# PCIe_SS1_PL_CONF register map
Vendor: Texas Instruments
Peripheral module from a debugger description file (folder DRA74xP_75xP_76xP_77xP).
Registers are 32-bit, read-write, reset 0x0 unless marked. A register's access mark holds for its fields unless they carry their own. Offsets are as the file gives them; lines under a group give offsets from that group; [hi:lo] are bit positions; {n}, {i} and the like mark numbered series; 'fields as' and 'values as' point back to an identical list; <NAME> marks a mode.

## PCIe_SS1_PL_CONF
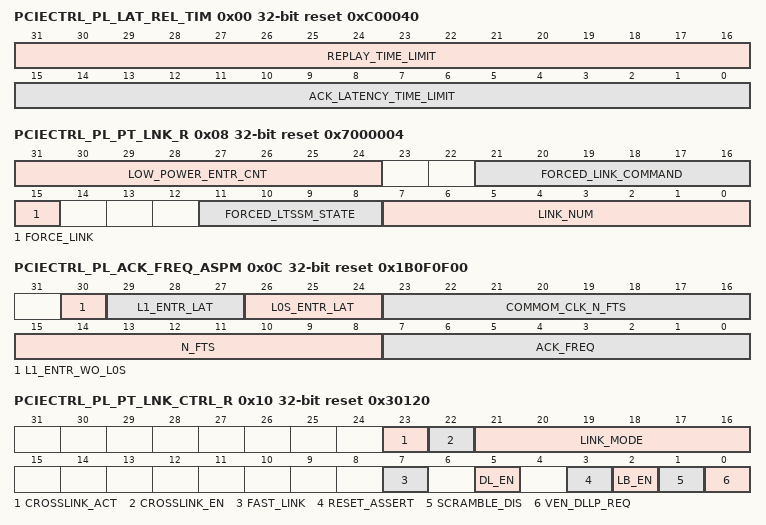
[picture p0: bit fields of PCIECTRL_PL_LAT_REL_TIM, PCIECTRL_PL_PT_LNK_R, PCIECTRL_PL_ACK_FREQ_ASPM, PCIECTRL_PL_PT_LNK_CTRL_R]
0x00 PCIECTRL_PL_LAT_REL_TIM reset 0xC00040 — Ack Latency and Replay Timer Register
  [31:16] REPLAY_TIME_LIMIT — The replay timer expires when it reaches this limit; The core initiates a replay upon reception of a Nak or when the replay timer expires; The default value depends on number of bytes (NB) per cycle, which is defined by the maximum core base frequency of the device PCIe core, corresponding to 250 MHz for PCIe-Gen2 (5 Gbps) operation. The default is then updated based on the Negotiated Link Width and Max_Payload_Size; Note: If operating at 5 Gb/s, then the rounded-up value of an additional (153/CX_NB) cycles is added, where CX_NB correspond to the number of PCIEPCS 8-bit input symbols per single 16-bit lane, that is, CX_NB=2. This means at 5Gbps, 77 extra cycles should be considered for the replay time limit. This is for additional internal processing for received TLPs and transmitted DLLPs.
  [15:0] ACK_LATENCY_TIME_LIMIT — The Ack/Nak latency timer expires when it reaches this limit; The default value depends on number of bytes (NB) per cycle, which is defined by the maximum core base frequency of the device PCIe core, corresponding to 250 MHz for PCIe-Gen2 (5 Gbps) operation. The default is then updated based on the Negotiated Link Width and Max_Payload_Size. Note: If operating at 5 Gb/s, then the rounded-up value of an additional (51 /CX_NB) cycles is added, where CX_NB correspond to the number of PCIEPCS 8-bit input symbols per single 16-bit lane, that is, CX_NB=2. This means at 5Gbps, 26 extra cycles should be considered for the acknowledge latency time limit. This is for additional internal processing for received TLPs and transmitted DLLPs.
0x04 PCIECTRL_PL_VENDOR_SPECIFIC_DLLP reset 0xFFFFFFFF — Vendor Specific DLLP Register
  [31:0] VEN_DLLP_REG — To send custom DLLP, write 8-bit DLLP Type and 24-bits of Payload data, then set PT_LNK_CTRL_R[0]
0x08 PCIECTRL_PL_PT_LNK_R access per field reset 0x7000004 — Port Force Link Register
  [31:24] LOW_POWER_ENTR_CNT rw — The Power Management state will wait for this many clock cycles for the associated completion of a CfgWr to D-state register to go low-power; This register is intended for applications that do not let the core handle a completion for configuration request to the PMCSCR register; Note: Only used in the DM core (in EP mode), EP core, and the Upstream Port of a Switch
  [21:16] FORCED_LINK_COMMAND rw — Link command transmitted by setting Force_Link (bit 15);
  [15] FORCE_LINK rw — Forces the LTSSM state and the Link command specified in this register; Self-clearing
    1=FORCE
  [11:8] FORCED_LTSSM_STATE rw — LTSSM state forced by setting Force_Link (bit 15)
  [7:0] LINK_NUM rw — Link Number; Not used for Endpoint
0x0C PCIECTRL_PL_ACK_FREQ_ASPM access per field reset 0x1B0F0F00 — Ack Frequency and L0-L1 ASPM Control Register (Sticky)
  [30] L1_ENTR_WO_L0S rw — Enter ASPM L1 without receive in L0s; Allow core to enter ASPM L1 even when link partner did not go to L0s (receive is not in L0s); When not set, core goes to ASPM L1 only after idle period during which both receive and transmit are in L0s
  [29:27] L1_ENTR_LAT rw — L1 Entrance Latency 0x0: 1 uS 0x1: 2 uS 0x2: 4 uS 0x3: 8 uS 0x4: 16 uS 0x5: 32 uS 0x6: 64 uS 0x7: 64 uS (alternate encoding)
  [26:24] L0S_ENTR_LAT rw — L0s Entrance Latency; Values correspond to: 0b000: 1 us 0b001: 2 us 0b010: 3 us 0b011: 4 us 0b100: 5 us 0b101: 6 us 0b110: 7 us 0b111: 7 us (alternate encoding)
  [23:16] COMMOM_CLK_N_FTS rw — Alternative N_FTS value, for common clock mode
  [15:8] N_FTS rw — Number of Fast Training Sequence (FTS) ordered sets to be transmitted when exiting L0s to L0; The maximum that can be requested is 255; Value 0 is not supported, and may cause LTSSM to go into Recovery upon L0s exit
  [7:0] ACK_FREQ rw — Ack Frequency; Number of pending ACKs accumulated before sending an ACK DLLP
0x10 PCIECTRL_PL_PT_LNK_CTRL_R access per field reset 0x30120 — Port Link Control Register (Sticky)
  [23] CROSSLINK_ACT ro — Crosslink Active
  [22] CROSSLINK_EN rw — Crosslink Enable
  [21:16] LINK_MODE rw — Link Mode Enable; Write 1 to bit N to enable (2**N)-lane mode 0x01: _1x 0x03: _2x 0x07: _4x
  [7] FAST_LINK rw — Fast Link Mode
  [5] DL_EN rw — DLL Link Enable
  [3] RESET_ASSERT rw
  [2] LB_EN rw — Loopback Enable
  [1] SCRAMBLE_DIS rw — Scramble Disable
  [0] VEN_DLLP_REQ rw — Vendor Specific DLLP transmit Request
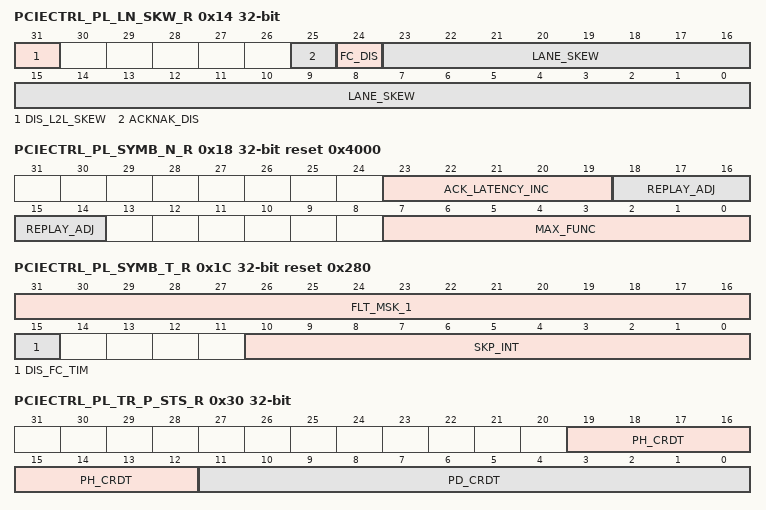
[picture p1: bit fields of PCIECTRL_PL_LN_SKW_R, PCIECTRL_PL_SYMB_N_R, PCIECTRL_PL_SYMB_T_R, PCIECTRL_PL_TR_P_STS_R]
0x14 PCIECTRL_PL_LN_SKW_R access per field — Lane Skew Register (Sticky)
  [31] DIS_L2L_SKEW rw — Disable Lane-to-Lane Deskew
  [25] ACKNAK_DIS rw — Ack/Nak Disable
  [24] FC_DIS rw — Flow Control Disable
  [23:0] LANE_SKEW rw — Insert Lane Skew for Transmit
0x18 PCIECTRL_PL_SYMB_N_R access per field reset 0x4000 — Timer Control and Symbol Number Register (Sticky)
  [23:19] ACK_LATENCY_INC rw — Timer Modifier for Ack/Nak Latency Timer
  [18:14] REPLAY_ADJ rw — Timer Modifier for Replay Timer
  [7:0] MAX_FUNC rw — Configuration Requests targeted at function numbers above this value will be returned with UR (unsupported request).
0x1C PCIECTRL_PL_SYMB_T_R access per field reset 0x280 — Symbol Timer Register and Filter Mask Register 1 (Sticky)
  [31:16] FLT_MSK_1 rw — Mask RADM Filtering and Error Handling Rules: Mask 1
  [15] DIS_FC_TIM rw — Disable FC Watchdog Timer
  [10:0] SKP_INT rw — SKP Interval Value minus one, PIPE clock cycles. (1 PIPE cycle = 2 symbols in 16-bit-per-lane PIPE)
0x20 PCIECTRL_PL_FL_MSK_R2 — Filter Mask Register 2 (Sticky)
  [31:0] FLT_MSK_2 — Mask RADM Filtering and Error Handling Rules: Mask 2
0x24 PCIECTRL_PL_OBNP_SUBREQ_CTRL access per field reset 0x1 — AXI Multiple Outbound Decomposed NP SubRequests Control Register (Sticky)
  [0] EN_OBNP_SUBREQ rw — Enable AXI Multiple Outbound Decomposed NP Sub-Requests.
0x30 PCIECTRL_PL_TR_P_STS_R ro — Transmit Posted FC Credit Status Register (Sticky)
  [19:12] PH_CRDT — Transmit Posted Header FC Credits
  [11:0] PD_CRDT — Transmit Posted Data FC Credits
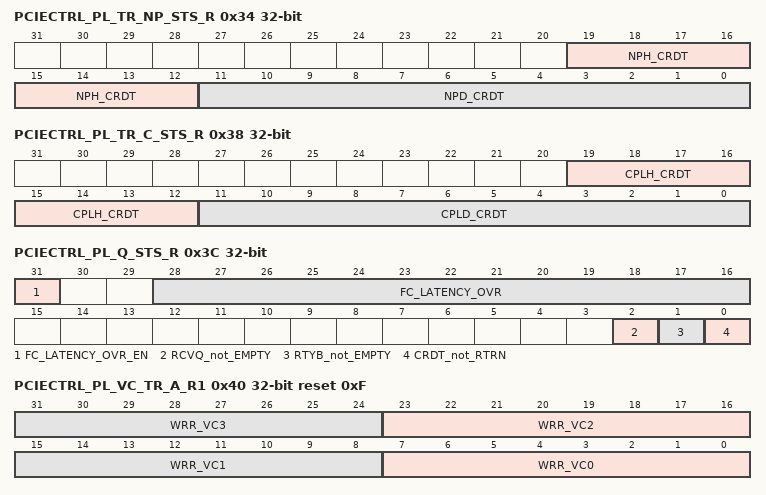
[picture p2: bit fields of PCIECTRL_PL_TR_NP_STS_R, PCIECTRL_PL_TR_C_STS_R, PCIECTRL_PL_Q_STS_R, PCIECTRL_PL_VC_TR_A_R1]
0x34 PCIECTRL_PL_TR_NP_STS_R ro — Transmit Non-Posted FC Credit Status Register (Sticky)
  [19:12] NPH_CRDT — Transmit Non-Posted Header FC Credits
  [11:0] NPD_CRDT — Transmit Non-Posted Data FC Credits
0x38 PCIECTRL_PL_TR_C_STS_R ro — Transmit Completion FC Credit Status Register (Sticky)
  [19:12] CPLH_CRDT — Transmit Completion Header FC Credits
  [11:0] CPLD_CRDT — Transmit Completion Data FC Credits
0x3C PCIECTRL_PL_Q_STS_R access per field — Queue Status Register (Sticky)
  [31] FC_LATENCY_OVR_EN rw — FC Latency Timer Override Enable
  [28:16] FC_LATENCY_OVR rw — FC Latency Timer Override Value
  [2] RCVQ_not_EMPTY ro — Received Queue Not Empty
  [1] RTYB_not_EMPTY ro — Transmit Retry Buffer Not Empty
  [0] CRDT_not_RTRN ro — Received TLP FC Credits Not Returned
0x40 PCIECTRL_PL_VC_TR_A_R1 ro reset 0xF — VC Transmit Arbitration Register 1 (Sticky)
  [8n+7:8n] WRR_VC{n} (n=0..3) — WRR Weight for VC{n}
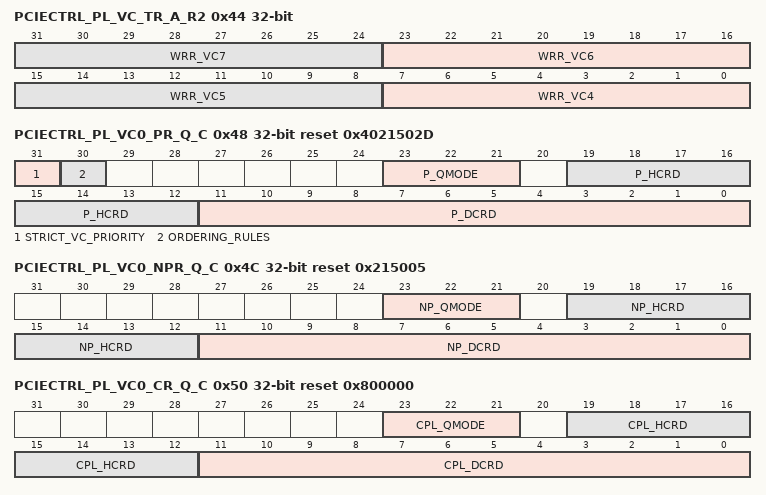
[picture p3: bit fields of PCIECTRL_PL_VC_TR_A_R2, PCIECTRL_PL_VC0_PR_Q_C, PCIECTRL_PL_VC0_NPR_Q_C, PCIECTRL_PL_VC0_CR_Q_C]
0x44 PCIECTRL_PL_VC_TR_A_R2 ro — VC Transmit Arbitration Register 2 (Sticky)
  [8n-25:8n-32] WRR_VC{n} (n=4..7) — WRR Weight for VC{n}
0x48 PCIECTRL_PL_VC0_PR_Q_C access per field reset 0x4021502D — VC0 Posted Receive Queue Control (Sticky)
  [31] STRICT_VC_PRIORITY rw — VC Ordering for Receive Queues
    0=ROUND_ROBIN; 1=STRICT (STRICT Ordering by VC)
  [30] ORDERING_RULES rw — VC0 TLP Type Ordering Rules
    0=STRICT (STRICT Posted, then Completion, then Non-Posted); 1=STANDARD (STANDARD As per PCIe standard)
  [23:21] P_QMODE rw — VC0 Poster TLP Queue Mode Read 0x1: STORE_AND_FORWARD Read 0x2: CUT_THROUGH Read 0x4: BYPASS Others: Reserved
  [19:12] P_HCRD ro — VC0 Posted Header Credits
  [11:0] P_DCRD ro — VC0 Posted Data Credits
0x4C PCIECTRL_PL_VC0_NPR_Q_C access per field reset 0x215005 — VC0 Non-Posted Receive Queue Control (Sticky)
  [23:21] NP_QMODE rw — VC0 Non-Poster TLP Queue Mode Read 0x1: STORE_AND_FORWARD Read 0x2: CUT_THROUGH Read 0x4: BYPASS Others: Reserved
  [19:12] NP_HCRD ro — VC0 Non-Posted Header Credits
  [11:0] NP_DCRD ro — VC0 Non-Posted Data Credits
0x50 PCIECTRL_PL_VC0_CR_Q_C access per field reset 0x800000 — VC0 Completion Receive Queue Control (Sticky)
  [23:21] CPL_QMODE rw — VC0 Completion TLP Queue Mode Read 0x1: STORE_AND_FORWARD Read 0x2: CUT_THROUGH Read 0x4: BYPASS
  [19:12] CPL_HCRD ro — VC0 Completion Header Credits
  [11:0] CPL_DCRD ro — VC0 Completion Data Credits
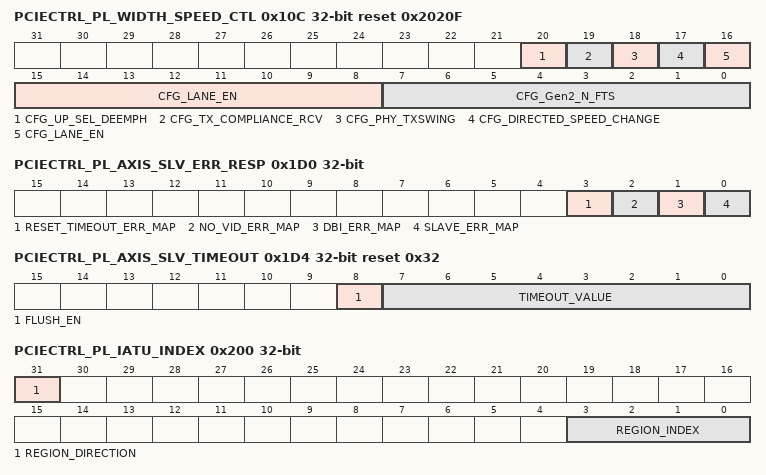
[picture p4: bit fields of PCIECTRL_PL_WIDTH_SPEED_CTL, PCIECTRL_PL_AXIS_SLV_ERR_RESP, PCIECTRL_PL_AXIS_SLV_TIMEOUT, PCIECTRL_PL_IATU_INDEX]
0x10C PCIECTRL_PL_WIDTH_SPEED_CTL access per field reset 0x2020F — Link Width and Speed Change Control Register (Sticky)
  [20] CFG_UP_SEL_DEEMPH rw — Used to set the de-emphasis level for Upstream Ports
  [19] CFG_TX_COMPLIANCE_RCV rw — Config Tx Compliance Receive Bit
  [18] CFG_PHY_TXSWING rw — Config PHY Tx Swing
  [17] CFG_DIRECTED_SPEED_CHANGE rw — Directed Speed Change
  [16:8] CFG_LANE_EN rw — Predetermined Number of Lanes
  [7:0] CFG_Gen2_N_FTS rw — Number of Fast Training Sequences
0x110 PCIECTRL_PL_PHY_STS_R ro — PHY Status Register (Sticky)
  [31:0] PHY_STS — PHY Status
0x114 PCIECTRL_PL_PHY_CTRL_R — PHY Control Register (Sticky)
  [31:0] PHY_CTRL — PHY Control
0x120 PCIECTRL_PL_MSI_CTRL_ADDRESS — MSI Controller Address Register (RC-mode MSI receiver)
  [31:0] MSI_CTRL_ADDRESS
0x124 PCIECTRL_PL_MSI_CTRL_UPPER_ADDRESS — MSI Controller Upper Address Register (RC-mode MSI receiver)
  [31:0] MSI_CTRL_UPPER_ADDRESS
{0x128+0xC*i} PCIECTRL_PL_MSI_CTRL_INT_ENABLE_N_{i} (i=0..7) — MSI Controller Interrupt #N Enable Register (RC-mode MSI receiver) with N = MSI data [7:5] and ENABLE[i] = enable MSI vector #i, with i = MSI data [4:0]
  [31:0] MSI_CTRL_INT_ENABLE — Status of an enabled bit (vectors) is set upon incoming MSI.
{0x12C+0xC*i} PCIECTRL_PL_MSI_CTRL_INT_MASK_N_{i} (i=0..7) — MSI Controller Interrupt #N Mask Register (RC-mode MSI receiver) with N = MSI data [7:5] and MASK[i] = mask of MSI vector #i, with i = MSI data [4:0]
  [31:0] MSI_CTRL_INT_MASK — Status of a masked bit (vector) triggers no IRQ to MPU when set.
{0x130+0xC*i} PCIECTRL_PL_MSI_CTRL_INT_STATUS_N_{i} (i=0..7) — MSI Controller Interrupt #N Status Register (RC-mode MSI receiver) with N = MSI data [7:5] and STATUS[i] = status of MSI vector #i, with i = MSI data [4:0]
  [31:0] MSI_CTRL_INT_STATUS — Status of an enabled bit (vectors) is set upon incoming MSI.
0x188 PCIECTRL_PL_MSI_CTRL_GPIO — MSI Controller General Purpose IO Register (RC-mode MSI receiver)
  [31:0] MSI_CTRL_GPIO
0x1B8 PCIECTRL_PL_PIPE_LOOPBACK access per field — PIPE loopback control register (Sticky)
  [31] LOOPBACK_EN rw — PIPE Loopback Enable
0x1BC PCIECTRL_PL_DBI_RO_WR_EN access per field reset 0x1 — DIF Read-Only register Write Enable (Sticky)
  [0] CX_DBI_RO_WR_EN rw — Control the writability over DIF of certain configuration fields that are RO over the PCIe wire
    0=WRDIS (WRDIS, RO fields are also RO over DIF; Use for RC mode (Type-1) config to mimic PCIe wire access when using DIF); 1=WREN (WREN, Some RO fields are writable over DIF)
0x1D0 PCIECTRL_PL_AXIS_SLV_ERR_RESP access per field — AXI Slave Error Response Register (Sticky)
  [3] RESET_TIMEOUT_ERR_MAP rw — Graceful Reset and Link Timeout Slave Error Response Mapping
  [2] NO_VID_ERR_MAP rw — Vendor ID Non-existent Slave Error Response Mapping
  [1] DBI_ERR_MAP rw — DIF Slave Error Response Mapping
  [0] SLAVE_ERR_MAP rw — Global Slave Error Response Mapping
0x1D4 PCIECTRL_PL_AXIS_SLV_TIMEOUT access per field reset 0x32 — Link Down AXI Slave Timeout Register (Sticky)
  [8] FLUSH_EN rw — Enable flush
  [7:0] TIMEOUT_VALUE rw — Timeout Value (ms)
0x200 PCIECTRL_PL_IATU_INDEX access per field — iATU Viewport Register: makes the registers of the corresponding iATU region accessible.
  [31] REGION_DIRECTION rw
    0=OUTBOUND; 1=INBOUND
  [3:0] REGION_INDEX rw — Outbound region, from 0 to 15. Inbound region, from 0 to 3.
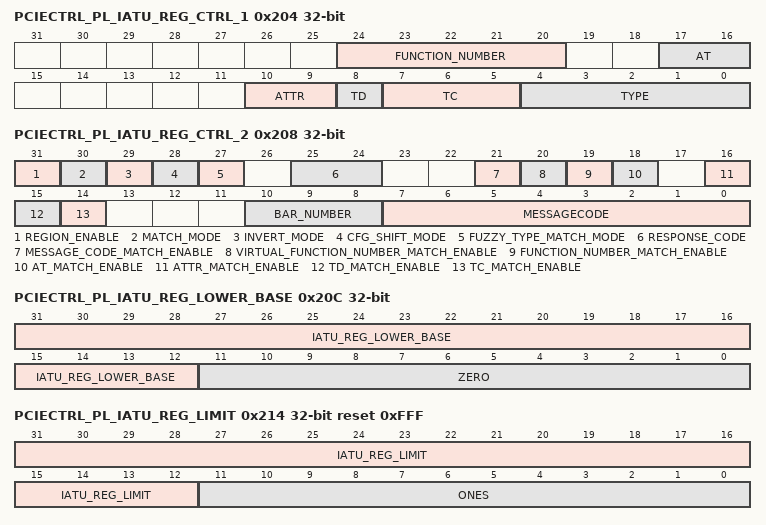
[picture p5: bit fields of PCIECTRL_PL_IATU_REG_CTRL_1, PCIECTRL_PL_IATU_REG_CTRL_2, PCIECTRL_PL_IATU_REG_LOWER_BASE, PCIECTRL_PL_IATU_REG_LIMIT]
0x204 PCIECTRL_PL_IATU_REG_CTRL_1 access per field — iATU Region Control 1 Register
  [24:20] FUNCTION_NUMBER rw — Outbound: F.N; applied to outgoing TLP (RID) with matching addess Inbound: F.N.-match criteria for incoming TLP (if Function_Number_match_enable=1)
  [17:16] AT rw — Outbound: AT applied to outgoing TLP with matching addess Inbound: AT-match criteria for matching TLP (if AT_match_enable=1)
  [10:9] ATTR rw — Outbound: ATTR applied to outgoing TLP with matching addess Inbound: ATTR-match criteria (if ATTR_match_enable=1)
  [8] TD rw — Outbound: TD applied to outgoing TLP with matching addess Inbound: TD-match criteria (if TD_match_enable=1)
  [7:5] TC rw — Outbound: TC applied to outgoing TLP with matching addess Inbound: TC-match criteria (if TC_match_enable=1)
  [4:0] TYPE rw — Outbound: TYPE applied to outgoing TLP with matching addess Inbound: TYPE-match criteria
0x208 PCIECTRL_PL_IATU_REG_CTRL_2 access per field — iATU Region Control 2 Register
  [31] REGION_ENABLE rw — Enable AT for this region
  [30] MATCH_MODE rw — Sets inbound TLP match mode, depending on TYPE
    0=MEM,I/O: Address Match: as per region base & limit registers; CFG0: Routing ID Match: Completer ID (BDF) + reg address matches base & limit-defined region; MSG[D]: Address Match: as per region base & limit registers; 1=MEM,I/O: BAR match: as defined in BAR_number field; CFG0: Accept mode: Completer ID (BDF) is ignored; MSG[D]: VendorID match: VendorID = upper_base[15:0] + VendorDefined = lower_base/limit
  [29] INVERT_MODE rw — Redefine match criteria as outside the defined range (instead of inside)
  [28] CFG_SHIFT_MODE rw — Enable the shifting of CFG CID (BDF), incoming and outgoing TLP; CFG get mapped to a contiguous 2**28 = 256 MByte address space Untranslated CID = CFG_DW#3[31:16] Shifted CID = CFG_DW#3[27:12]
  [27] FUZZY_TYPE_MATCH_MODE rw — Outbound: DMA Bypass Mode Inbound: Relax matching on inbound TLP TYPE: CfgRd0 == CfgRd1 CfgWr0 == CfgWr1 MRd == MRdLk routing field of Msg/MsgD ignored
  [25:24] RESPONSE_CODE rw — Override HW-generated completion status when responding inbound TLP 0x0: No override, use HW-generated CS 0x1: Unsupported Request: CS= 3'b001 0x2: Completer Abort: CS= 3'b100
  [21] MESSAGE_CODE_MATCH_ENABLE rw — Enable MessageCode match criteria on inbound TLP
  [20] VIRTUAL_FUNCTION_NUMBER_MATCH_ENABLE rw — VIRTUAL FUNCTIONS not IMPLEMENTED: not USED
  [19] FUNCTION_NUMBER_MATCH_ENABLE rw — Outbound: Function Number Translation Bypass Inbound: Enable Function Number match criteria
  [18] AT_MATCH_ENABLE rw — Enable AT match criteria on inbound TLP ATS not SUPPORTED: DO not USE
  [16] ATTR_MATCH_ENABLE rw — Enable ATTR match criteria on inbound TLP
  [15] TD_MATCH_ENABLE rw — Enable TD match criteria on inbound TLP
  [14] TC_MATCH_ENABLE rw — Enable TC match criteria on inbound TLP
  [10:8] BAR_NUMBER rw — BAR number for mayching with incoming MEM, I/O TLP (if Match_Mode = 1) 0x0: BAR0 0x1: BAR1 0x2: BAR2 0x3: BAR3 0x4: BAR4 0x5: BAR5 0x6: ROM
  [7:0] MESSAGECODE rw — Outbound: MessageCode applied to outgoing message TLP with matching addess Inbound: MessageCode-match criteria for infoming message TLP (if Message_Code_match_enable=1)
0x20C PCIECTRL_PL_IATU_REG_LOWER_BASE access per field — iATU Region Lower Base Address Register (2**12 = 4kbyte - aligned)
  [31:12] IATU_REG_LOWER_BASE rw, [11:0] ZERO ro
0x210 PCIECTRL_PL_IATU_REG_UPPER_BASE — iATU Region Upper Base Address Register
  [31:0] IATU_REG_UPPER_BASE
0x214 PCIECTRL_PL_IATU_REG_LIMIT access per field reset 0xFFF — iATU Region Limit Address Register
  [31:12] IATU_REG_LIMIT rw, [11:0] ONES ro
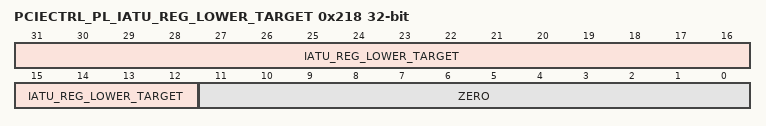
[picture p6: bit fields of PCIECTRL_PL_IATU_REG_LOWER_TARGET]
0x218 PCIECTRL_PL_IATU_REG_LOWER_TARGET access per field — iATU Region Lower Target Address Register (2**12 = 4kbyte - aligned)
  [31:12] IATU_REG_LOWER_TARGET rw, [11:0] ZERO ro
0x21C PCIECTRL_PL_IATU_REG_UPPER_TARGET — iATU Region Upper Target Address Register
  [31:0] IATU_REG_UPPER_TARGET
0x220 PCIECTRL_PL_IATU_REG_CTRL_3 ro — iATU Region Control 3 Register; VIRTUAL FUNCTIONS not IMPLEMENTED: not USED
  [31:0] IATU_REG_CTRL_3
